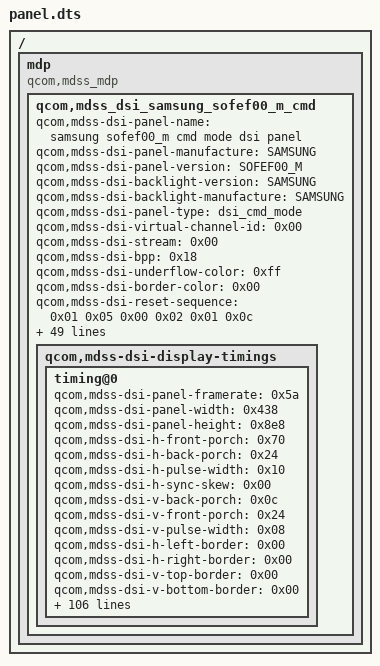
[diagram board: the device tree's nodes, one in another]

/dts-v1/;

/ {
	mdp {
		compatible = "qcom,mdss_mdp";

        qcom,mdss_dsi_samsung_sofef00_m_cmd {
            qcom,mdss-dsi-panel-name = "samsung sofef00_m cmd mode dsi panel";
            qcom,mdss-dsi-panel-manufacture = "SAMSUNG";
            qcom,mdss-dsi-panel-version = "SOFEF00_M";
            qcom,mdss-dsi-backlight-version = "SAMSUNG";
            qcom,mdss-dsi-backlight-manufacture = "SAMSUNG";
            qcom,mdss-dsi-panel-type = "dsi_cmd_mode";
            qcom,mdss-dsi-virtual-channel-id = <0x00>;
            qcom,mdss-dsi-stream = <0x00>;
            qcom,mdss-dsi-bpp = <0x18>;
            qcom,mdss-dsi-underflow-color = <0xff>;
            qcom,mdss-dsi-border-color = <0x00>;
            qcom,mdss-dsi-reset-sequence = <0x01 0x05 0x00 0x02 0x01 0x0c>;
            qcom,mdss-pan-physical-width-dimension = <0x44>;
            qcom,mdss-pan-physical-height-dimension = <0x91>;
            qcom,mdss-dsi-traffic-mode = "burst_mode";
            qcom,mdss-dsi-bllp-eof-power-mode;
            qcom,mdss-dsi-bllp-power-mode;
            qcom,mdss-dsi-lane-0-state;
            qcom,mdss-dsi-lane-1-state;
            qcom,mdss-dsi-lane-2-state;
            qcom,mdss-dsi-lane-3-state;
            qcom,mdss-dsi-dma-trigger = "trigger_sw";
            qcom,mdss-dsi-mdp-trigger = "none";
            qcom,mdss-dsi-te-pin-select = <0x01>;
            qcom,mdss-dsi-wr-mem-start = <0x2c>;
            qcom,mdss-dsi-wr-mem-continue = <0x3c>;
            qcom,mdss-dsi-te-dcs-command = <0x01>;
            qcom,mdss-dsi-te-check-enable;
            qcom,mdss-dsi-te-using-te-pin;
            qcom,mdss-dsi-lp11-init;
            qcom,mdss-dsi-high-brightness-panel;
            qcom,mdss-dsi-acl-cmd-index = <0x00>;
            qcom,mdss-dsi-acl-mode-index = <0x01>;
            qcom,mdss-bl-high2bit;
            qcom,mdss-dsi-panel-status-check-mode = "te_signal_check";
            qcom,mdss-dsi-panel-seria-num-year-index = <0x0c>;
            qcom,mdss-dsi-panel-seria-num-mon-index = <0x0c>;
            qcom,mdss-dsi-panel-seria-num-day-index = <0x0d>;
            qcom,mdss-dsi-panel-seria-num-hour-index = <0x0e>;
            qcom,mdss-dsi-panel-seria-num-min-index = <0x0f>;
            qcom,ulps-enabled;
            qcom,mdss-dsi-panel-hdr-enabled;
            qcom,mdss-dsi-panel-hdr-color-primaries = <0x3d13 0x4042 0x84d0 0x3e80 0x33c2 0x86c4 0x1d4c 0xbb8>;
            qcom,mdss-dsi-panel-peak-brightness = <0x5265c0>;
            qcom,mdss-dsi-panel-average-brightness = <0x1e8480>;
            qcom,mdss-dsi-panel-blackness-level = <0x7d0>;
            qcom,panel-supply-entries = <0x45>;
            qcom,mdss-dsi-bl-pmic-control-type = "bl_ctrl_dcs";
            qcom,mdss-brightness-max-level = <0x3ff>;
            qcom,mdss-dsi-bl-min-level = <0x01>;
            qcom,mdss-dsi-bl-max-level = <0x3ff>;
            qcom,platform-reset-gpio = <0xffffffff 0x06 0x00>;
            qcom,platform-vci-gpio = <0xffffffff 0x1a 0x00>;
            qcom,platform-poc-gpio = <0xffffffff 0x19 0x00>;
            qcom,mdss-dsi-t-clk-post = <0x0e>;
            qcom,mdss-dsi-t-clk-pre = <0x36>;
            qcom,mdss-panel-mismatch-check;
            phandle = <0x57>;

            qcom,mdss-dsi-display-timings {

                timing@0 {
                    qcom,mdss-dsi-panel-framerate = <0x5a>;
                    qcom,mdss-dsi-panel-width = <0x438>;
                    qcom,mdss-dsi-panel-height = <0x8e8>;
                    qcom,mdss-dsi-h-front-porch = <0x70>;
                    qcom,mdss-dsi-h-back-porch = <0x24>;
                    qcom,mdss-dsi-h-pulse-width = <0x10>;
                    qcom,mdss-dsi-h-sync-skew = <0x00>;
                    qcom,mdss-dsi-v-back-porch = <0x0c>;
                    qcom,mdss-dsi-v-front-porch = <0x24>;
                    qcom,mdss-dsi-v-pulse-width = <0x08>;
                    qcom,mdss-dsi-h-left-border = <0x00>;
                    qcom,mdss-dsi-h-right-border = <0x00>;
                    qcom,mdss-dsi-v-top-border = <0x00>;
                    qcom,mdss-dsi-v-bottom-border = <0x00>;
                    qcom,mdss-dsi-panel-jitter = <0x08 0x0a>;
                    qcom,mdss-dsi-on-command = [05 01 00 00 0a 00 02 11 00 39 01 00 00 00 00 03 f0 5a 5a 15 01 00 00 00 00 02 35 00 39 01 00 00 00 00 03 f0 a5 a5 39 01 00 00 00 00 03 f0 5a 5a 15 01 00 00 00 00 02 b0 07 15 01 00 00 00 00 02 b6 12 39 01 00 00 00 00 03 f0 a5 a5 15 01 00 00 00 00 02 53 20 15 01 00 00 00 00 02 55 00 05 01 00 00 00 00 02 29 00];
                    qcom,mdss-dsi-off-command = [05 01 00 00 28 00 02 28 00 05 01 00 00 a0 00 02 10 00];
                    qcom,mdss-dsi-seed-command = [29 01 00 00 00 00 03 f0 5a 5a 29 01 00 00 00 00 03 e2 00 41 29 01 00 00 00 00 02 b0 2c 29 01 00 00 00 00 14 e2 b4 02 04 05 ff 02 00 00 ff 00 ff ff f0 e0 e1 18 ff f3 f8 29 01 00 00 00 00 03 f0 a5 a5];
                    qcom,mdss-dsi-panel-command = [29 01 00 00 00 00 03 f0 5a 5a 29 01 00 00 00 00 03 e2 00 41 29 01 00 00 00 00 02 b0 2c 29 01 00 00 00 00 14 e2 b4 02 04 05 ff 02 00 00 ff 00 ff ff f0 e0 e1 18 ff f3 f8 29 01 00 00 00 00 03 f0 a5 a5];
                    qcom,mdss-dsi-panel-command-state = "dsi_lp_mode";
                    qcom,mdss-dsi-seed-command-state = "dsi_lp_mode";
                    qcom,mdss-dsi-on-command-state = "dsi_lp_mode";
                    qcom,mdss-dsi-off-command-state = "dsi_hs_mode";
                    qcom,mdss-dsi-h-sync-pulse = <0x00>;
                    qcom,mdss-dsi-panel-acl-command = [15 01 00 00 00 00 02 55 00];
                    qcom,mdss-dsi-acl-command-state = "dsi_hs_mode";
                    qcom,mdss-dsi-panel-hbm-on-command = <0x39010000 0x3f0 0x5a5a1501 0x4000 0x253e839 0x1000010 0x3b202 0xd4150100 0x02 0xf7033901 0x00 0x3f0a5a5>;
                    qcom,mdss-dsi-panel-hbm-on-command-2 = <0x39010000 0x3f0 0x5a5a1501 0x4000 0x253e839 0x1000010 0x3b202 0x3c150100 0x02 0xf7033901 0x00 0x3f0a5a5>;
                    qcom,mdss-dsi-panel-hbm-on-command-3 = <0x39010000 0x3f0 0x5a5a1501 0x4000 0x253e839 0x1000010 0x3b201 0x9c150100 0x02 0xf7033901 0x00 0x3f0a5a5>;
                    qcom,mdss-dsi-panel-hbm-on-command-4 = <0x39010000 0x3f0 0x5a5a1501 0x4000 0x253e839 0x1000010 0x3b200 0xf0150100 0x02 0xf7033901 0x00 0x3f0a5a5>;
                    qcom,mdss-dsi-panel-hbm-on-command-5 = <0x39010000 0x3f0 0x5a5a1501 0x4000 0x253e839 0x1000010 0x3b200 0x40150100 0x02 0xf7033901 0x00 0x3f0a5a5>;
                    qcom,mdss-dsi-panel-hbm-off-command = [39 01 00 00 00 00 03 f0 5a 5a 15 01 00 00 00 00 02 53 28 15 01 00 00 00 00 02 f7 03 39 01 00 00 00 00 03 f0 a5 a5];
                    qcom,mdss-dsi-panel-hbm-max-brightness-command-on = <0x39010000 0x3f0 0x5a5a1501 0x4000 0x253e839 0x1000010 0x3b200 0x40150100 0x02 0xf7033901 0x00 0x3f0a5a5>;
                    qcom,mdss-dsi-panel-hbm-max-brightness-command-off = [39 01 00 00 00 00 03 f0 5a 5a 15 01 00 00 00 00 02 53 28 15 01 00 00 00 00 02 f7 03 39 01 00 00 00 00 03 f0 a5 a5];
                    qcom,mdss-dsi-hbm-on-command-state = "dsi_lp_mode";
                    qcom,mdss-dsi-hbm-off-command-state = "dsi_lp_mode";
                    qcom,mdss-dsi-panel-hbm-max-brightness-command-on-state = "dsi_lp_mode";
                    qcom,mdss-dsi-panel-hbm-max-brightness-command-off-state = "dsi_lp_mode";
                    qcom,mdss-dsi-panel-aod-on-command-1;
                    qcom,mdss-dsi-panel-aod-on-command-2;
                    qcom,mdss-dsi-panel-aod-on-command-3;
                    qcom,mdss-dsi-panel-aod-on-command-4;
                    qcom,mdss-dsi-panel-aod-off-command;
                    qcom,mdss-dsi-panel-aod-mode-command-1 = [39 01 00 00 00 00 03 f0 5a 5a 15 01 00 00 00 00 02 53 23 05 01 00 00 01 00 02 39 00 39 01 00 00 00 00 03 f0 a5 a5];
                    qcom,mdss-dsi-panel-aod-mode-command-2 = [39 01 00 00 00 00 03 f0 5a 5a 15 01 00 00 00 00 02 53 22 05 01 00 00 01 00 02 39 00 39 01 00 00 00 00 03 f0 a5 a5];
                    qcom,mdss-dsi-panel-aod-mode-command-3 = [39 01 00 00 00 00 03 f0 5a 5a 15 01 00 00 00 00 02 53 23 05 01 00 00 01 00 02 38 00 39 01 00 00 00 00 03 f0 a5 a5];
                    qcom,mdss-dsi-panel-aod-mode-command-4 = [39 01 00 00 00 00 03 f0 5a 5a 15 01 00 00 00 00 02 53 22 05 01 00 00 01 00 02 38 00 39 01 00 00 00 00 03 f0 a5 a5];
                    qcom,mdss-dsi-aod-on-command-state = "dsi_lp_mode";
                    qcom,mdss-dsi-aod-off-command-state = "dsi_lp_mode";
                    qcom,mdss-dsi-aod-mode-command-state = "dsi_lp_mode";
                    qcom,mdss-dsi-panel-serial-num-command = <0x6010000 0x1a1>;
                    qcom,mdss-dsi-panel-serial-num-command-state = "dsi_lp_mode";
                    qcom,mdss-dsi-panel-display-srgb-color-mode-on-command = [39 01 00 00 00 00 03 f0 5a 5a 39 01 00 00 00 00 03 e2 00 85 39 01 00 00 00 00 02 b0 2c 39 01 00 00 00 00 16 e2 cc 06 06 48 f8 18 01 01 d7 4f fe fd d0 12 e0 ff fb 1d ff ff fc 39 01 00 00 00 00 02 b0 49 39 01 00 00 00 00 02 e2 00 39 01 00 00 00 00 02 b0 4a 39 01 00 00 00 00 02 e2 00 39 01 00 00 00 00 02 b0 4b 39 01 00 00 00 00 02 e2 00 39 01 00 00 00 00 02 b0 4c 39 01 00 00 00 00 02 e2 00 39 01 00 00 00 00 02 b0 4d 39 01 00 00 00 00 02 e2 00 39 01 00 00 00 00 03 f0 a5 a5];
                    qcom,mdss-dsi-panel-display-p3-mode-on-command = [39 01 00 00 00 00 03 f0 5a 5a 39 01 00 00 00 00 03 e2 00 85 39 01 00 00 00 00 02 b0 2c 39 01 00 00 00 00 16 e2 ff 00 00 12 f0 00 02 02 e9 19 ff fc ed 03 ec fc f9 00 ff ff fd 39 01 00 00 00 00 02 b0 49 39 01 00 00 00 00 02 e2 00 39 01 00 00 00 00 02 b0 4a 39 01 00 00 00 00 02 e2 00 39 01 00 00 00 00 02 b0 4b 39 01 00 00 00 00 02 e2 00 39 01 00 00 00 00 02 b0 4c 39 01 00 00 00 00 02 e2 00 39 01 00 00 00 00 02 b0 4d 39 01 00 00 00 00 02 e2 00 39 01 00 00 00 00 03 f0 a5 a5];
                    qcom,mdss-dsi-panel-display-wide-color-mode-on-command = [39 01 00 00 00 00 03 f0 5a 5a 39 01 00 00 00 00 03 e2 00 85 39 01 00 00 00 00 02 b0 2c 39 01 00 00 00 00 16 e2 ff 00 00 00 ff 00 00 00 ff 00 ff ff ff 00 ff ff ff 00 ff ff ff 39 01 00 00 00 00 02 b0 49 39 01 00 00 00 00 02 e2 00 39 01 00 00 00 00 02 b0 4a 39 01 00 00 00 00 02 e2 00 39 01 00 00 00 00 02 b0 4b 39 01 00 00 00 00 02 e2 00 39 01 00 00 00 00 02 b0 4c 39 01 00 00 00 00 02 e2 00 39 01 00 00 00 00 02 b0 4d 39 01 00 00 00 00 02 e2 00 39 01 00 00 00 00 03 f0 a5 a5];
                    qcom,mdss-dsi-panel-dci-p3-off-command = [39 01 00 00 00 00 03 f0 5a 5a 39 01 00 00 00 00 03 e2 00 40 39 01 00 00 00 00 03 f0 a5 a5];
                    qcom,mdss-dsi-customer-srgb-enable-command = [39 01 00 00 00 00 03 f0 5a 5a 39 01 00 00 00 00 03 e2 00 85 39 01 00 00 00 00 02 b0 2c 39 01 00 00 00 00 16 e2 cc 06 06 48 f8 18 01 01 d7 4f fe fd d0 12 e0 ff fb 1d ff ff fc 39 01 00 00 00 00 02 b0 49 39 01 00 00 00 00 02 e2 00 39 01 00 00 00 00 02 b0 4a 39 01 00 00 00 00 02 e2 00 39 01 00 00 00 00 02 b0 4b 39 01 00 00 00 00 02 e2 00 39 01 00 00 00 00 02 b0 4c 39 01 00 00 00 00 02 e2 00 39 01 00 00 00 00 02 b0 4d 39 01 00 00 00 00 02 e2 00 39 01 00 00 00 00 03 f0 a5 a5];
                    qcom,mdss-dsi-customer-p3-enable-command = [39 01 00 00 00 00 03 f0 5a 5a 39 01 00 00 00 00 03 e2 00 85 39 01 00 00 00 00 02 b0 2c 39 01 00 00 00 00 16 e2 ff 00 00 12 f0 00 02 02 e9 19 ff fc ed 03 ec fc f9 00 ff ff fd 39 01 00 00 00 00 02 b0 49 39 01 00 00 00 00 02 e2 00 39 01 00 00 00 00 02 b0 4a 39 01 00 00 00 00 02 e2 00 39 01 00 00 00 00 02 b0 4b 39 01 00 00 00 00 02 e2 00 39 01 00 00 00 00 02 b0 4c 39 01 00 00 00 00 02 e2 00 39 01 00 00 00 00 02 b0 4d 39 01 00 00 00 00 02 e2 00 39 01 00 00 00 00 03 f0 a5 a5];
                    qcom,mdss-dsi-customer-p3-enable-command-state = "dsi_lp_mode";
                    qcom,mdss-dsi-customer-srgb-enable-command-state = "dsi_lp_mode";
                    qcom,mdss-dsi-laoding-effect-enable-command-state = "dsi_lp_mode";
                    qcom,mdss-dsi-laoding-effect-disable-command-state = "dsi_lp_mode";
                    qcom,mdss-dsi-panel-display-srgb-color-mode-on-command-state = "dsi_lp_mode";
                    qcom,mdss-dsi-panel-display-p3-mode-on-command-state = "dsi_lp_mode";
                    qcom,mdss-dsi-panel-display-wide-color-mode-on-command-state = "dsi_lp_mode";
                    qcom,mdss-dsi-panel-night-mode-on-command-state = "dsi_lp_mode";
                    qcom,mdss-dsi-panel-dci-p3-off-command-state = "dsi_lp_mode";
                    qcom,mdss-dsi-panel-status-command = [06 01 00 01 05 00 02 0a 08];
                    qcom,mdss-dsi-panel-status-command-state = "dsi_lp_mode";
                    qcom,mdss-dsi-panel-id-command = [06 01 00 01 05 00 02 dc 08];
                    qcom,mdss-dsi-panel-id-command-state = "dsi_lp_mode";
                    qcom,mdss-dsi-panel-phy-timings = <0x230909 0x26240909 0x6030400>;
                    qcom,display-topology = <0x01 0x00 0x01>;
                    qcom,default-topology-index = <0x00>;
                };
            };
		};
	};
};
